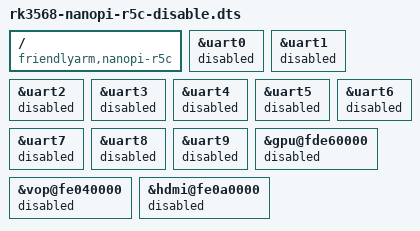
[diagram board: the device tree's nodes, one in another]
/dts-v1/;
/plugin/;


/ {
	compatible = "friendlyarm,nanopi-r5c\0rockchip,rk3568";
	fragment@0 {
		target = <&uart0>;

		__overlay__ {
			status = "disabled";
				};
			};

	fragment@1 {
		target = <&uart1>;

		__overlay__ {
			status = "disabled";
				};
			};
		
	fragment@2 {
		target = <&uart2>;

		__overlay__ {
			status = "disabled";
				};
			};

	fragment@3 {
		target = <&uart3>;

		__overlay__ {
			status = "disabled";
				};
			};

	fragment@4 {
		target = <&uart4>;

		__overlay__ {
			status = "disabled";
				};
			};

	fragment@5 {
		target = <&uart5>;

		__overlay__ {
			status = "disabled";
				};
			};

	fragment@6 {
		target = <&uart6>;

		__overlay__ {
			status = "disabled";
				};
			};

	fragment@7 {
		target = <&uart7>;

		__overlay__ {
			status = "disabled";
				};
			};

	fragment@8 {
		target = <&uart8>;

		__overlay__ {
			status = "disabled";
				};
			};

	fragment@9 {
		target = <&uart9>;

		__overlay__ {
			status = "disabled";
				};
			};

	fragment@10 {
		target-path = "gpu@fde60000";

		__overlay__ {
			status = "disabled";
				};
			};

	fragment@11 {
		target-path = "vop@fe040000";

		__overlay__ {
			status = "disabled";
				};
			};

	fragment@12 {
		target-path = "hdmi@fe0a0000";

		__overlay__ {
			status = "disabled";
				};
			};

	};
